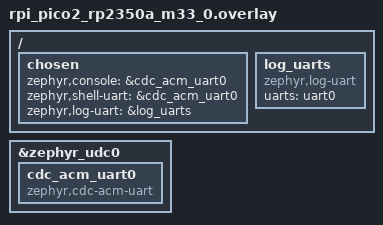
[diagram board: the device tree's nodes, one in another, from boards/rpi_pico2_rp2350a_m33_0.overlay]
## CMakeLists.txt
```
# SPDX-License-Identifier: Apache-2.0

cmake_minimum_required(VERSION 3.28.0)
find_package(Zephyr REQUIRED HINTS $ENV{ZEPHYR_BASE})
project(pico2_app)

target_sources(app PRIVATE
    src/main.c
    src/app.c
)
```

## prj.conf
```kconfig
# SPDX-License-Identifier: Apache-2.0
#
# Application Kconfig. Merged on top of the board defconfig, which already
# enables CONSOLE, SERIAL, UART_CONSOLE, GPIO, CLOCK_CONTROL, RESET and the
# HEX/UF2 build outputs, so those are intentionally not repeated here.
#
# Debug-only options live in debug.conf, see README.md.
#
# Serial role map (devices are chosen in boards/*.overlay):
#   console -> cdc_acm_uart0 (USB)  zephyr,console
#   shell   -> cdc_acm_uart0 (USB)  zephyr,shell-uart
#   logs    -> uart0 (GP0/GP1)      zephyr,log-uart + LOG_BACKEND_UART
# Recipes for moving any of these: see DEBUG_CONFIG.md.

CONFIG_GPIO=y

# Logging. The board overlay routes log output to UART0 (GP0/GP1) through the
# `zephyr,log-uart` chosen node, independently of the console device.
CONFIG_LOG=y
CONFIG_LOG_DEFAULT_LEVEL=3
CONFIG_LOG_BACKEND_UART=y

# Thread names are visible in `info threads` (GDB) and in crash dumps.
CONFIG_THREAD_NAME=y

# Console and interactive shell on the Pico 2 native USB (CDC-ACM).
CONFIG_SHELL=y
CONFIG_SHELL_BACKEND_SERIAL=y
# Keep logs out of the shell stream: they belong to the UART0 backend.
CONFIG_SHELL_LOG_BACKEND=n
CONFIG_SHELL_BACKEND_SERIAL_RX_RING_BUFFER_SIZE=128
CONFIG_SHELL_BACKEND_SERIAL_TX_RING_BUFFER_SIZE=128
CONFIG_USB_DEVICE_STACK_NEXT=y
CONFIG_CDC_ACM_SERIAL_INITIALIZE_AT_BOOT=y
CONFIG_CDC_ACM_SERIAL_PID=0x0004
CONFIG_CDC_ACM_SERIAL_PRODUCT_STRING="pico2-app console"
CONFIG_UART_LINE_CTRL=y
CONFIG_STDOUT_CONSOLE=y

CONFIG_MAIN_STACK_SIZE=2048
```

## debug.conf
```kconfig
# SPDX-License-Identifier: Apache-2.0
#
# Debug-only Kconfig fragment. Kept out of prj.conf so release builds stay
# small. Use it with:
#
#   west build -p always -b rpi_pico2/rp2350a/m33_0 . -- -DEXTRA_CONF_FILE=debug.conf
#
# or simply `make build`.

# Thread awareness for the SEGGER Zephyr RTOS plugin (GDB `info threads`).
CONFIG_DEBUG_THREAD_INFO=y
CONFIG_THREAD_STACK_INFO=y

# -Og instead of -O2: line stepping that matches the source.
CONFIG_DEBUG_OPTIMIZATIONS=y

# Second log channel over RTT, in addition to the UART0 backend in prj.conf.
# Used by `west rtt --runner jlink`.
CONFIG_USE_SEGGER_RTT=y
CONFIG_LOG_BACKEND_RTT=y
CONFIG_LOG_MODE_IMMEDIATE=y
```

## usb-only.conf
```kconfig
# SPDX-License-Identifier: Apache-2.0
#
# Single-cable experiment: console + shell + logs all on the USB CDC-ACM port.
# Used as an extra fragment, so prj.conf stays untouched:
#
#   make build EXTRA_CONF="debug.conf;usb-only.conf"
#   make flash
#
# Rollback: `make build && make flash` (debug.conf only).

# Print log records through the shell instead of a dedicated UART backend.
CONFIG_SHELL_LOG_BACKEND=y

# No logs on the external USB-UART converter.
CONFIG_LOG_BACKEND_UART=n

# debug.conf selects CONFIG_LOG_MODE_IMMEDIATE. The shell log backend in
# immediate mode drives cdc_acm_poll_out() directly, which drops bytes for a
# CDC-ACM port (no TX work is scheduled without echo mitigation): log lines
# arrive truncated and the prompt disappears. Deferred mode keeps the shell's
# interrupt-driven transport and only hands records to the shell thread.
CONFIG_LOG_MODE_DEFERRED=y

# A colorized log line plus the prompt redraw exceeds prj.conf's 128-byte ring,
# so the shell dropped bytes in the middle of records.
CONFIG_SHELL_BACKEND_SERIAL_TX_RING_BUFFER_SIZE=1024
```

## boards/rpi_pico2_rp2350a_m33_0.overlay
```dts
/*
 * Copyright (c) 2026 Dante Sangiorgio
 *
 * SPDX-License-Identifier: Apache-2.0
 *
 * Console and shell live on the Pico 2 native USB port (CDC-ACM).
 * Application logs are routed to UART0 (GP0 = TX, GP1 = RX), which is where
 * the external USB-UART converter is connected.
 *
 * Serial role map:
 *   console -> cdc_acm_uart0 (USB)  zephyr,console
 *   shell   -> cdc_acm_uart0 (USB)  zephyr,shell-uart
 *   logs    -> uart0 (GP0/GP1)      zephyr,log-uart
 * Recipes for moving any of these: see DEBUG_CONFIG.md.
 */

/ {
	chosen {
		zephyr,console = &cdc_acm_uart0;
		zephyr,shell-uart = &cdc_acm_uart0;
		zephyr,log-uart = &log_uarts;
	};

	log_uarts: log_uarts {
		compatible = "zephyr,log-uart";
		uarts = <&uart0>;
	};
};

&zephyr_udc0 {
	cdc_acm_uart0: cdc_acm_uart0 {
		compatible = "zephyr,cdc-acm-uart";
	};
};
```

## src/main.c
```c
/*
 * Copyright (c) 2026 Dante Sangiorgio
 *
 * SPDX-License-Identifier: Apache-2.0
 */

#include <zephyr/kernel.h>
#include <zephyr/logging/log.h>

#include "app.h"

LOG_MODULE_REGISTER(pico2_app, LOG_LEVEL_INF);

int main(void)
{
	int ret;

	LOG_INF("booting on %s", CONFIG_BOARD_TARGET);

	ret = app_init();
	if (ret < 0) {
		LOG_ERR("app_init() failed (%d), halting", ret);
		return ret;
	}

	LOG_INF("app_init() done, entering main loop");
	app_run();

	return 0;
}
```

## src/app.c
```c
/*
 * Copyright (c) 2026 Dante Sangiorgio
 *
 * SPDX-License-Identifier: Apache-2.0
 */

#include <zephyr/kernel.h>
#include <zephyr/drivers/gpio.h>
#include <zephyr/logging/log.h>

#include "app.h"

/* Defined (and registered) in main.c, declared here: one log module per app. */
LOG_MODULE_DECLARE(pico2_app);

#define LED0_NODE       DT_ALIAS(led0)
#define BLINK_PERIOD_MS 1000

#if !DT_NODE_HAS_STATUS(LED0_NODE, okay)
#error "This application needs an enabled led0 devicetree alias"
#endif

/* The Pico 2 user LED is GPIO25, exposed by the board as led0. */
static const struct gpio_dt_spec led = GPIO_DT_SPEC_GET(LED0_NODE, gpios);

int app_init(void)
{
	if (!gpio_is_ready_dt(&led)) {
		LOG_ERR("GPIO controller for led0 is not ready");
		return -ENODEV;
	}

	if (gpio_pin_configure_dt(&led, GPIO_OUTPUT_INACTIVE) < 0) {
		LOG_ERR("failed to configure led0 as an output");
		return -EIO;
	}

	return 0;
}

void app_run(void)
{
	uint32_t heartbeat = 0U;

	while (true) {
		bool on = (heartbeat % 2U) == 0U;

		if (gpio_pin_set_dt(&led, on) < 0) {
			LOG_ERR("failed to drive led0");
			return;
		}

		LOG_INF("heartbeat %u: LED %s", heartbeat, on ? "ON" : "OFF");
		heartbeat++;
		k_msleep(BLINK_PERIOD_MS);
	}
}
```

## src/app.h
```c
/*
 * Copyright (c) 2026 Dante Sangiorgio
 *
 * SPDX-License-Identifier: Apache-2.0
 */

#ifndef APP_H_
#define APP_H_

/**
 * @brief Initialise application resources (GPIO, sensors, timers, ...).
 *
 * @return 0 on success, negative errno on failure.
 */
int app_init(void);

/**
 * @brief Run the application main loop.
 *
 * Does not return under normal operation.
 */
void app_run(void);

#endif /* APP_H_ */
```
